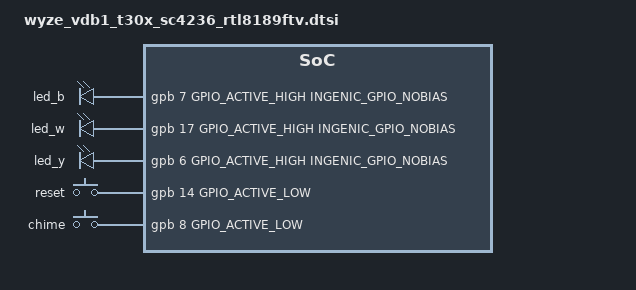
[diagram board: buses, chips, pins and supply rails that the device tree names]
// Wyze Video Doorbell v1 (T30X, SC4236, RTL8189FTV) per-board GPIO definitions.
// Injected into the kernel 4.4+ device tree; ignored on 3.10.

#include <dt-bindings/gpio/gpio.h>
#include <dt-bindings/input/input.h>
#include <dt-bindings/pinctrl/ingenic-pinctrl.h>

/ {
	gpio-leds {
		compatible = "gpio-leds";

		led_b {
			label = "led_b";
			gpios = <&gpb 7 GPIO_ACTIVE_HIGH INGENIC_GPIO_NOBIAS>;
			default-state = "off";
		};

		led_w {
			label = "led_w";
			gpios = <&gpb 17 GPIO_ACTIVE_HIGH INGENIC_GPIO_NOBIAS>;
			default-state = "off";
		};

		led_y {
			label = "led_y";
			gpios = <&gpb 6 GPIO_ACTIVE_HIGH INGENIC_GPIO_NOBIAS>;
			default-state = "off";
		};
	};
};

/ {
	gpio-keys {
		compatible = "gpio-keys";
		label = "gpio-keys";

		reset {
			label = "reset";
			linux,code = <KEY_ENTER>;
			gpios = <&gpb 14 GPIO_ACTIVE_LOW INGENIC_GPIO_PULLUP>;
		};

		chime {
			label = "chime";
			linux,code = <KEY_1>;
			gpios = <&gpb 8 GPIO_ACTIVE_LOW INGENIC_GPIO_PULLUP>;
		};
	};
};
